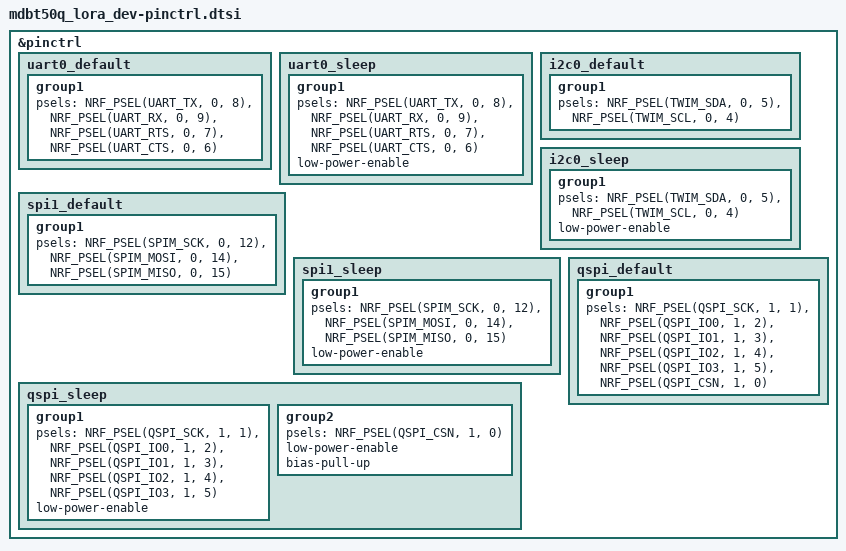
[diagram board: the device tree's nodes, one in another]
/*
 * Copyright (c) 2024 Regis Rousseau
 * SPDX-License-Identifier: Apache-2.0
 */

&pinctrl {
	/* USB to UART Converter */
	uart0_default: uart0_default {
		group1 {
			psels = <NRF_PSEL(UART_TX, 0, 8)>,
				    <NRF_PSEL(UART_RX, 0, 9)>,
				    <NRF_PSEL(UART_RTS, 0, 7)>,
				    <NRF_PSEL(UART_CTS, 0, 6)>;
		};
	};

	uart0_sleep: uart0_sleep {
		group1 {
			psels = <NRF_PSEL(UART_TX, 0, 8)>,
				    <NRF_PSEL(UART_RX, 0, 9)>,
				    <NRF_PSEL(UART_RTS, 0, 7)>,
				    <NRF_PSEL(UART_CTS, 0, 6)>;
			low-power-enable;
		};
	};
	
	/* I2C Device : SHT31 (0x44) & RTC (0x68) */
	i2c0_default: i2c0_default {
		group1 {
			psels = <NRF_PSEL(TWIM_SDA, 0, 5)>,
				    <NRF_PSEL(TWIM_SCL, 0, 4)>;
				    //bias-disable;
				    //bias-pull-up;
		};
	};

	i2c0_sleep: i2c0_sleep {
		group1 {
			psels = <NRF_PSEL(TWIM_SDA, 0, 5)>,
				    <NRF_PSEL(TWIM_SCL, 0, 4)>;
			low-power-enable;
		};
	};
	
	/* SPI1 : RFM95W module */
	spi1_default: spi1_default {
		group1 {
			psels = <NRF_PSEL(SPIM_SCK, 0, 12)>,
				     <NRF_PSEL(SPIM_MOSI, 0, 14)>,
				     <NRF_PSEL(SPIM_MISO, 0, 15)>;
		};
	};

	spi1_sleep: spi1_sleep {
		group1 {
			psels = <NRF_PSEL(SPIM_SCK, 0, 12)>,
				    <NRF_PSEL(SPIM_MOSI, 0, 14)>,
				    <NRF_PSEL(SPIM_MISO, 0, 15)>;
			low-power-enable;
		};
	};
	
	/* QSPI : MX25R6435FM1 Flash Memory */
	qspi_default: qspi_default {
		group1 {
			psels = <NRF_PSEL(QSPI_SCK, 1, 1)>,
				    <NRF_PSEL(QSPI_IO0, 1, 2)>,
				    <NRF_PSEL(QSPI_IO1, 1, 3)>,
				    <NRF_PSEL(QSPI_IO2, 1, 4)>,
				    <NRF_PSEL(QSPI_IO3, 1, 5)>,
				    <NRF_PSEL(QSPI_CSN, 1, 0)>;
		};
	};

	qspi_sleep: qspi_sleep {
		group1 {
			psels = <NRF_PSEL(QSPI_SCK, 1, 1)>,
				    <NRF_PSEL(QSPI_IO0, 1, 2)>,
				    <NRF_PSEL(QSPI_IO1, 1, 3)>,
				    <NRF_PSEL(QSPI_IO2, 1, 4)>,
				    <NRF_PSEL(QSPI_IO3, 1, 5)>;
			low-power-enable;
		};
		group2 {
			psels = <NRF_PSEL(QSPI_CSN, 1, 0)>;
			low-power-enable;
			bias-pull-up;
		};
	};

};
